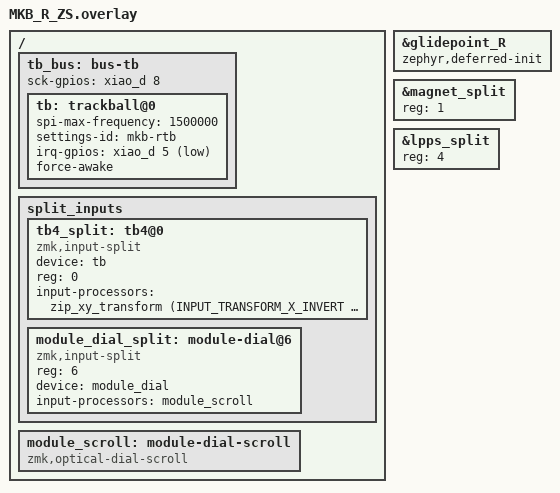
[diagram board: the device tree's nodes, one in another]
/* Reuse each module's established calibration, pinout and input processors. */
#include "zeroshift_devices.dtsi"
#define right_encoder joy_encoder
#include "joy_r.dtsi"
#undef right_encoder
#include "rzt_r.dtsi"
#include "tpd_r.dtsi"
/* TWIM0 and SPIM0 share an nRF peripheral; use SPIM2 for the LPPS bus. */
#define spi0 spi2
#include "lpps_r.dtsi"
#undef spi0
#include "zeroshift_common.dtsi"
&glidepoint_R { zephyr,deferred-init; };
&magnet_split { reg = <1>; };
&lpps_split { reg = <4>; };

/ {
    tb_bus: bus-tb {
        #include "zeroshift_tb_bus.dtsi"
        sck-gpios = <&xiao_d 8 GPIO_ACTIVE_HIGH>;
        tb: trackball@0 {
            #include "zeroshift_tb_sensor.dtsi"
            spi-max-frequency = <1500000>;
            settings-id = "mkb-rtb";
            irq-gpios = <&xiao_d 5 (GPIO_ACTIVE_LOW | GPIO_PULL_UP)>;
            force-awake;
        };
    };
    split_inputs {
        tb4_split: tb4@0 {
            compatible = "zmk,input-split";
            device = <&tb>;
            reg = <0>;
            input-processors = <&zip_xy_transform (INPUT_TRANSFORM_X_INVERT | INPUT_TRANSFORM_Y_INVERT)>;
        };
    };
};

#include "zeroshift_dial.dtsi"

/ {
    module_scroll: module-dial-scroll {
        compatible = "zmk,optical-dial-scroll";
        #input-processor-cells = <0>;
    };
    split_inputs {
        module_dial_split: module-dial@6 {
            compatible = "zmk,input-split";
            reg = <6>;
            device = <&module_dial>;
            input-processors = <&module_scroll>;
        };
    };
};
